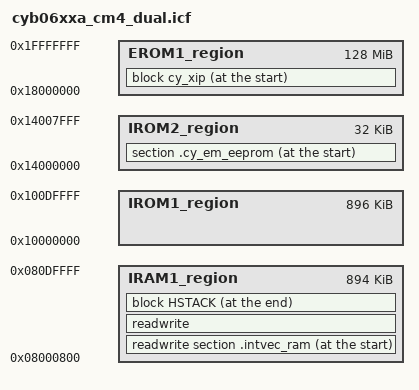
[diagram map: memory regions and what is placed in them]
/*******************************************************************************
* \file cyb06xxa_cm4_dual.icf
* \version 2.91
*
* Linker file for the IAR compiler.
*
* The main purpose of the linker script is to describe how the sections in the
* input files should be mapped into the output file, and to control the memory
* layout of the output file.
*
* \note The entry point is fixed and starts at 0x10000000. The valid application
* image should be placed there.
*
* \note The linker files included with the PDL template projects must be generic
* and handle all common use cases. Your project may not use every section
* defined in the linker files. In that case you may see warnings during the
* build process. In your project, you can simply comment out or remove the
* relevant code in the linker file.
*
********************************************************************************
* \copyright
* Copyright 2016-2021 Cypress Semiconductor Corporation
* SPDX-License-Identifier: Apache-2.0
*
* Licensed under the Apache License, Version 2.0 (the "License");
* you may not use this file except in compliance with the License.
* You may obtain a copy of the License at
*
*     http://www.apache.org/licenses/LICENSE-2.0
*
* Unless required by applicable law or agreed to in writing, software
* distributed under the License is distributed on an "AS IS" BASIS,
* WITHOUT WARRANTIES OR CONDITIONS OF ANY KIND, either express or implied.
* See the License for the specific language governing permissions and
* limitations under the License.
*******************************************************************************/

/*###ICF### Section handled by ICF editor, don't touch! ****/
/*-Editor annotation file-*/
/* IcfEditorFile="$TOOLKIT_DIR$\config\ide\IcfEditor\cortex_v1_4.xml" */
/*-Specials-*/
define symbol __ICFEDIT_intvec_start__ = 0x00000000;

/* The symbols below define the location and size of blocks of memory in the target.
 * Use these symbols to specify the memory regions available for allocation.
 */

/* The following symbols control RAM and flash memory allocation for the CM4 core.
 * You can change the memory allocation by editing RAM and Flash symbols.
 * Your changes must be aligned with the corresponding symbols for CM0+ core in 'xx_cm0plus.icf',
 * where 'xx' is the device group; for example, 'cyb06xx7_cm0plus.icf'.
 */
/* RAM */
define symbol __ICFEDIT_region_IRAM1_start__ = 0x08000800;
define symbol __ICFEDIT_region_IRAM1_end__   = 0x080DFFFF;

/* Flash */
define symbol __ICFEDIT_region_IROM1_start__ = 0x10000000;
define symbol __ICFEDIT_region_IROM1_end__   = 0x100DFFFF;

/* The following symbols define a 32K flash region used for EEPROM emulation.
 * This region can also be used as the general purpose flash.
 * You can assign sections to this memory region for only one of the cores.
 * Note some middleware (e.g. BLE, Emulated EEPROM) can place their data into this memory region.
 * Therefore, repurposing this memory region will prevent such middleware from operation.
 */
define symbol __ICFEDIT_region_IROM2_start__ = 0x14000000;
define symbol __ICFEDIT_region_IROM2_end__   = 0x14007FFF;

/* The following symbols define device specific memory regions and must not be changed. */
/* XIP */
define symbol __ICFEDIT_region_EROM1_start__ = 0x18000000;
define symbol __ICFEDIT_region_EROM1_end__   = 0x1FFFFFFF;

define symbol __ICFEDIT_region_EROM2_start__ = 0x0;
define symbol __ICFEDIT_region_EROM2_end__   = 0x0;
define symbol __ICFEDIT_region_EROM3_start__ = 0x0;
define symbol __ICFEDIT_region_EROM3_end__   = 0x0;


define symbol __ICFEDIT_region_IRAM2_start__ = 0x0;
define symbol __ICFEDIT_region_IRAM2_end__   = 0x0;
define symbol __ICFEDIT_region_ERAM1_start__ = 0x0;
define symbol __ICFEDIT_region_ERAM1_end__   = 0x0;
define symbol __ICFEDIT_region_ERAM2_start__ = 0x0;
define symbol __ICFEDIT_region_ERAM2_end__   = 0x0;
define symbol __ICFEDIT_region_ERAM3_start__ = 0x0;
define symbol __ICFEDIT_region_ERAM3_end__   = 0x0;
/*-Sizes-*/
if (!isdefinedsymbol(__STACK_SIZE)) {
  define symbol __ICFEDIT_size_cstack__ = 0x1000;
} else {
  define symbol __ICFEDIT_size_cstack__ = __STACK_SIZE;
}
define symbol __ICFEDIT_size_proc_stack__ = 0x0;

/* Defines the minimum heap size. The actual heap size will be expanded to the end of the stack region */
if (!isdefinedsymbol(__HEAP_SIZE)) {
    define symbol __ICFEDIT_size_heap__ = 0x0400;
} else {
  define symbol __ICFEDIT_size_heap__ = __HEAP_SIZE;
}
/**** End of ICF editor section. ###ICF###*/

/* The size of the MCU boot header area at the start of FLASH */
define symbol BOOT_HEADER_SIZE  = 0x400;

/* The size of the Cortex-M0+ application image (including MCU boot header area) */
define symbol FLASH_CM0P_SIZE  = 0x10000;

define memory mem with size = 4G;
define region IROM1_region = mem:[from __ICFEDIT_region_IROM1_start__ to __ICFEDIT_region_IROM1_end__];
define region IROM2_region = mem:[from __ICFEDIT_region_IROM2_start__ to __ICFEDIT_region_IROM2_end__];
define region EROM1_region = mem:[from __ICFEDIT_region_EROM1_start__ to __ICFEDIT_region_EROM1_end__];
define region IRAM1_region = mem:[from __ICFEDIT_region_IRAM1_start__ to __ICFEDIT_region_IRAM1_end__];

define block CSTACK     with alignment = 8, size = __ICFEDIT_size_cstack__     { };
define block PROC_STACK with alignment = 8, size = __ICFEDIT_size_proc_stack__ { };
define block HEAP       with expanding size, alignment = 8, minimum size = __ICFEDIT_size_heap__ { };
define block HSTACK {block HEAP, block PROC_STACK, last block CSTACK};
define block CM0P_RO with size = (FLASH_CM0P_SIZE - BOOT_HEADER_SIZE)  { readonly section .cy_m0p_image };
define block RO     {first section .intvec, readonly};

define block cy_xip { section .cy_xip };

/*-Initializations-*/
initialize by copy { readwrite };
do not initialize  { section .noinit, section .intvec_ram };

/*-Placement-*/

/* Flash - Cortex-M0+ application image */
place at address (__ICFEDIT_region_IROM1_start__ + BOOT_HEADER_SIZE)  { block CM0P_RO };

/* Flash - Cortex-M4 application */
place at address (__ICFEDIT_region_IROM1_start__ + FLASH_CM0P_SIZE) { block RO };

/* Used for the digital signature of the secure application and the Bootloader SDK application. */
".cy_app_signature" : place at address (__ICFEDIT_region_IROM1_end__ - 0x200) { section .cy_app_signature };

/* Emulated EEPROM Flash area */
".cy_em_eeprom" : place at start of IROM2_region  { section .cy_em_eeprom };

/* Execute in Place (XIP). See the smif driver documentation for details. */
"cy_xip" : place at start of EROM1_region  { block cy_xip };

/* RAM */
place at start of IRAM1_region  { readwrite section .intvec_ram};
place in          IRAM1_region  { readwrite };
place at end   of IRAM1_region  { block HSTACK };

keep {  section .cy_m0p_image,
        section .cy_app_signature,
        section .cy_em_eeprom,
        section .cy_xip,
         };



/* EOF */
